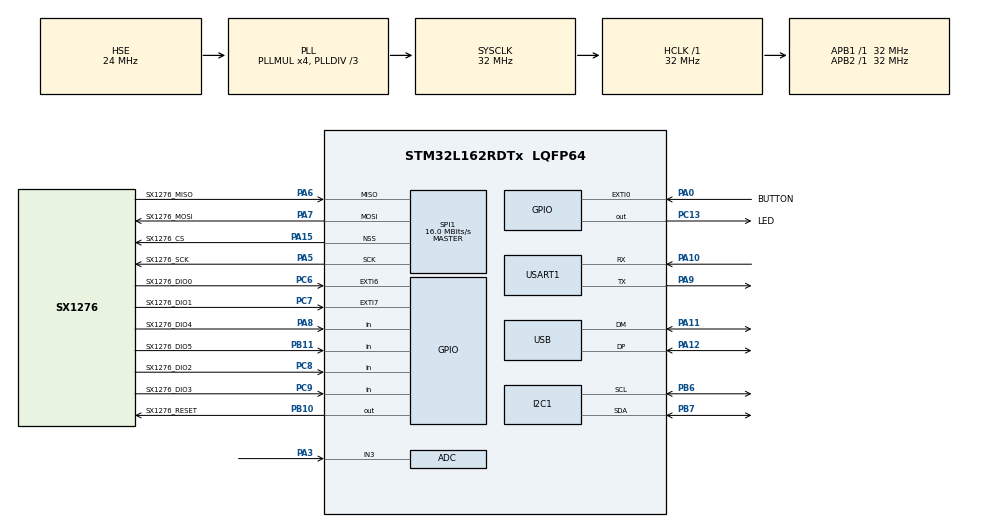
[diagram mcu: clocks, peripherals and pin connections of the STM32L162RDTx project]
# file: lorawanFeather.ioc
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ADC.Channel-1\#ChannelRegularConversion=ADC_CHANNEL_3
ADC.NbrOfConversionFlag=1
ADC.Rank-1\#ChannelRegularConversion=1
ADC.SamplingTime-1\#ChannelRegularConversion=ADC_SAMPLETIME_4CYCLES
Dma.Request0=USART1_TX
Dma.USART1_TX.0.Direction=DMA_MEMORY_TO_PERIPH
Dma.USART1_TX.0.Instance=DMA1_Channel4
Dma.USART1_TX.0.MemDataAlignment=DMA_MDATAALIGN_BYTE
Dma.USART1_TX.0.MemInc=DMA_MINC_ENABLE
Dma.USART1_TX.0.Mode=DMA_NORMAL
Dma.USART1_TX.0.PeriphDataAlignment=DMA_PDATAALIGN_BYTE
Dma.USART1_TX.0.PeriphInc=DMA_PINC_DISABLE
Dma.USART1_TX.0.Priority=DMA_PRIORITY_LOW
Mcu.Family=STM32L1
Mcu.Name=STM32L162RDTx
Mcu.Package=LQFP64
NVIC.DMA1_Channel4_IRQn=true\:0\:0\:false\:false\:true\:false\:true
NVIC.EXTI0_IRQn=true\:0\:0\:false\:false\:true\:true\:true
NVIC.EXTI9_5_IRQn=true\:0\:0\:false\:false\:true\:true\:true
NVIC.I2C1_ER_IRQn=true\:0\:0\:false\:false\:true\:true\:true
NVIC.I2C1_EV_IRQn=true\:0\:0\:false\:false\:true\:true\:true
NVIC.PVD_IRQn=true\:0\:0\:false\:false\:true\:true\:true
NVIC.PriorityGroup=NVIC_PRIORITYGROUP_4
NVIC.RCC_IRQn=true\:0\:0\:false\:false\:true\:true\:false
NVIC.RTC_Alarm_IRQn=true\:0\:0\:false\:false\:true\:true\:true
NVIC.SPI1_IRQn=true\:0\:0\:false\:false\:true\:true\:true
NVIC.USART1_IRQn=true\:0\:0\:false\:false\:true\:true\:true
NVIC.USB_LP_IRQn=true\:0\:0\:false\:false\:true\:false\:true
PA0-WKUP1.GPIO_Label=BUTTON
PA0-WKUP1.Signal=GPXTI0
PA10.Mode=Asynchronous
PA10.Signal=USART1_RX
PA11.Mode=Device
PA11.Signal=USB_DM
PA12.Mode=Device
PA12.Signal=USB_DP
PA13.Mode=Trace_Asynchronous_SW
PA13.Signal=SYS_JTMS-SWDIO
PA14.Mode=Trace_Asynchronous_SW
PA14.Signal=SYS_JTCK-SWCLK
PA15.GPIO_Label=SX1276_CS
PA15.Mode=NSS_Signal_Hard_Output
PA15.Signal=SPI1_NSS
PA3.Mode=IN3
PA3.Signal=ADC_IN3
PA5.GPIO_Label=SX1276_SCK
PA5.Mode=Full_Duplex_Master
PA5.Signal=SPI1_SCK
PA6.GPIO_Label=SX1276_MISO
PA6.Mode=Full_Duplex_Master
PA6.Signal=SPI1_MISO
PA7.GPIO_Label=SX1276_MOSI
PA7.Mode=Full_Duplex_Master
PA7.Signal=SPI1_MOSI
PA8.GPIO_Label=SX1276_DIO4
PA8.Signal=GPIO_Input
PA9.Mode=Asynchronous
PA9.Signal=USART1_TX
PB10.GPIO_Label=SX1276_RESET
PB10.Signal=GPIO_Output
PB11.GPIO_Label=SX1276_DIO5
PB11.Signal=GPIO_Input
PB3.Mode=Trace_Asynchronous_SW
PB3.Signal=SYS_JTDO-TRACESWO
PB6.Mode=I2C
PB6.Signal=I2C1_SCL
PB7.Mode=I2C
PB7.Signal=I2C1_SDA
PC13-WKUP2.GPIO_Label=LED
PC13-WKUP2.Signal=GPIO_Output
PC14-OSC32_IN.Mode=LSE-External-Oscillator
PC14-OSC32_IN.Signal=RCC_OSC32_IN
PC15-OSC32_OUT.Mode=LSE-External-Oscillator
PC15-OSC32_OUT.Signal=RCC_OSC32_OUT
PC6.GPIO_Label=SX1276_DIO0
PC6.Signal=GPXTI6
PC7.GPIO_Label=SX1276_DIO1
PC7.Signal=GPXTI7
PC8.GPIO_Label=SX1276_DIO2
PC8.Signal=GPIO_Input
PC9.GPIO_Label=SX1276_DIO3
PC9.Signal=GPIO_Input
PH0-OSC_IN.Mode=HSE-External-Oscillator
PH0-OSC_IN.Signal=RCC_OSC_IN
PH1-OSC_OUT.Mode=HSE-External-Oscillator
PH1-OSC_OUT.Signal=RCC_OSC_OUT
ProjectManager.HeapSize=0x200
ProjectManager.StackSize=0x400
ProjectManager.TargetToolchain=Makefile
RCC.48MHZClocksFreq_Value=48000000
RCC.AHBFreq_Value=32000000
RCC.APB1Freq_Value=32000000
RCC.APB1TimFreq_Value=32000000
RCC.APB2Freq_Value=32000000
RCC.APB2TimFreq_Value=32000000
RCC.HCLKFreq_Value=32000000
RCC.HSE_VALUE=24000000
RCC.HSI_VALUE=16000000
RCC.MSI_VALUE=2097000
RCC.PLLDIV=RCC_PLL_DIV3
RCC.PLLMUL=RCC_PLL_MUL4
RCC.SYSCLKFreq_VALUE=32000000
RCC.SYSCLKSource=RCC_SYSCLKSOURCE_PLLCLK
RCC.VCOOutputFreq_Value=96000000
RTC.Alarm-Alarm\ A=RTC_ALARM_A
SPI1.CalculateBaudRate=16.0 MBits/s
SPI1.Direction=SPI_DIRECTION_2LINES
SPI1.Mode=SPI_MODE_MASTER
SPI1.VirtualNSS=VM_NSSHARD
SPI1.VirtualType=VM_MASTER
USART1.VirtualMode=VM_ASYNC
USB_DEVICE.CLASS_NAME_FS=CDC
USB_DEVICE.VirtualMode=Cdc
USB_DEVICE.VirtualModeFS=Cdc_FS
VP_ADC_Channel3SpeedFast.Mode=Channel3SpeedFast
VP_RTC_VS_RTC_Activate.Mode=RTC_Enabled
VP_RTC_VS_RTC_Alarm_A_Intern.Mode=Alarm A
VP_RTC_VS_RTC_Calendar.Mode=RTC_Calendar
VP_SYS_V_PVD_IN.Mode=Mode_PVD_Int
VP_USB_DEVICE_VS_USB_DEVICE_CDC_FS.Mode=CDC_FS
board=custom

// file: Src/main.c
/* USER CODE BEGIN Header */
/**
  ******************************************************************************
  * @file           : main.c
  * @brief          : Main program body
  ******************************************************************************
  * @attention
  *
  * <h2><center>&copy; Copyright (c) 2019 STMicroelectronics.
  * All rights reserved.</center></h2>
  *
  * This software component is licensed by ST under Ultimate Liberty license
  * SLA0044, the "License"; You may not use this file except in compliance with
  * the License. You may obtain a copy of the License at:
  *                             www.st.com/SLA0044
  *
  ******************************************************************************
  */
/* USER CODE END Header */

#include "main.h"
#include "usb_device.h"

/* USER CODE BEGIN Includes */
#include "lora.h"
#include "uart_printf.h"

/* USER CODE END Includes */

ADC_HandleTypeDef hadc;

I2C_HandleTypeDef hi2c1;

RTC_HandleTypeDef hrtc;

SPI_HandleTypeDef hspi1;

UART_HandleTypeDef huart1;
DMA_HandleTypeDef hdma_usart1_tx;

void SystemClock_Config(void);
static void MX_GPIO_Init(void);
static void MX_DMA_Init(void);
static void MX_SPI1_Init(void);
static void MX_I2C1_Init(void);
static void MX_USART1_UART_Init(void);
static void MX_RTC_Init(void);
static void MX_ADC_Init(void);

int main(void)
{

  /* MCU Configuration--------------------------------------------------------*/

  /* Reset of all peripherals, Initializes the Flash interface and the Systick. */
  HAL_Init();

  /* Configure the system clock */
  SystemClock_Config();

  /* Initialize all configured peripherals */
  MX_GPIO_Init();
  MX_DMA_Init();
  MX_SPI1_Init();
  MX_I2C1_Init();
  MX_USB_DEVICE_Init();
  MX_USART1_UART_Init();
  MX_RTC_Init();
  MX_ADC_Init();

  /* Infinite loop */
  while (1)
  {
    asm("nop");
  }
}

void SystemClock_Config(void)
{
  RCC_OscInitTypeDef RCC_OscInitStruct = {0};
  RCC_ClkInitTypeDef RCC_ClkInitStruct = {0};
  RCC_PeriphCLKInitTypeDef PeriphClkInit = {0};

  /** Configure the main internal regulator output voltage
  */
  __HAL_PWR_VOLTAGESCALING_CONFIG(PWR_REGULATOR_VOLTAGE_SCALE1);
  /** Initializes the CPU, AHB and APB busses clocks
  */
  RCC_OscInitStruct.OscillatorType = RCC_OSCILLATORTYPE_HSI|RCC_OSCILLATORTYPE_LSI
                              |RCC_OSCILLATORTYPE_HSE;
  RCC_OscInitStruct.HSEState = RCC_HSE_ON;
  RCC_OscInitStruct.HSIState = RCC_HSI_ON;
  RCC_OscInitStruct.HSICalibrationValue = RCC_HSICALIBRATION_DEFAULT;
  RCC_OscInitStruct.LSIState = RCC_LSI_ON;
  RCC_OscInitStruct.PLL.PLLState = RCC_PLL_ON;
  RCC_OscInitStruct.PLL.PLLSource = RCC_PLLSOURCE_HSE;
  RCC_OscInitStruct.PLL.PLLMUL = RCC_PLL_MUL4;
  RCC_OscInitStruct.PLL.PLLDIV = RCC_PLL_DIV3;
  if (HAL_RCC_OscConfig(&RCC_OscInitStruct) != HAL_OK)
  {
    Error_Handler();
  }
  /** Initializes the CPU, AHB and APB busses clocks
  */
  RCC_ClkInitStruct.ClockType = RCC_CLOCKTYPE_HCLK|RCC_CLOCKTYPE_SYSCLK
                              |RCC_CLOCKTYPE_PCLK1|RCC_CLOCKTYPE_PCLK2;
  RCC_ClkInitStruct.SYSCLKSource = RCC_SYSCLKSOURCE_PLLCLK;
  RCC_ClkInitStruct.AHBCLKDivider = RCC_SYSCLK_DIV1;
  RCC_ClkInitStruct.APB1CLKDivider = RCC_HCLK_DIV1;
  RCC_ClkInitStruct.APB2CLKDivider = RCC_HCLK_DIV1;

  if (HAL_RCC_ClockConfig(&RCC_ClkInitStruct, FLASH_LATENCY_1) != HAL_OK)
  {
    Error_Handler();
  }
  PeriphClkInit.PeriphClockSelection = RCC_PERIPHCLK_RTC;
  PeriphClkInit.RTCClockSelection = RCC_RTCCLKSOURCE_LSI;
  if (HAL_RCCEx_PeriphCLKConfig(&PeriphClkInit) != HAL_OK)
  {
    Error_Handler();
  }
}

static void MX_ADC_Init(void)
{

  ADC_ChannelConfTypeDef sConfig = {0};

  /** Configure the global features of the ADC (Clock, Resolution, Data Alignment and number of conversion)
  */
  hadc.Instance = ADC1;
  hadc.Init.ClockPrescaler = ADC_CLOCK_ASYNC_DIV1;
  hadc.Init.Resolution = ADC_RESOLUTION_12B;
  hadc.Init.DataAlign = ADC_DATAALIGN_RIGHT;
  hadc.Init.ScanConvMode = ADC_SCAN_DISABLE;
  hadc.Init.EOCSelection = ADC_EOC_SEQ_CONV;
  hadc.Init.LowPowerAutoWait = ADC_AUTOWAIT_DISABLE;
  hadc.Init.LowPowerAutoPowerOff = ADC_AUTOPOWEROFF_DISABLE;
  hadc.Init.ChannelsBank = ADC_CHANNELS_BANK_A;
  hadc.Init.ContinuousConvMode = DISABLE;
  hadc.Init.NbrOfConversion = 1;
  hadc.Init.DiscontinuousConvMode = DISABLE;
  hadc.Init.ExternalTrigConv = ADC_SOFTWARE_START;
  hadc.Init.ExternalTrigConvEdge = ADC_EXTERNALTRIGCONVEDGE_NONE;
  hadc.Init.DMAContinuousRequests = DISABLE;
  if (HAL_ADC_Init(&hadc) != HAL_OK)
  {
    Error_Handler();
  }
  /** Configure the channel speed in Fast mode
  */
  __HAL_ADC_CHANNEL_SPEED_FAST(ADC_CHANNEL_3);
  /** Configure for the selected ADC regular channel its corresponding rank in the sequencer and its sample time.
  */
  sConfig.Channel = ADC_CHANNEL_3;
  sConfig.Rank = ADC_REGULAR_RANK_1;
  sConfig.SamplingTime = ADC_SAMPLETIME_4CYCLES;
  if (HAL_ADC_ConfigChannel(&hadc, &sConfig) != HAL_OK)
  {
    Error_Handler();
  }

}

static void MX_I2C1_Init(void)
{

  hi2c1.Instance = I2C1;
  hi2c1.Init.ClockSpeed = 100000;
  hi2c1.Init.DutyCycle = I2C_DUTYCYCLE_2;
  hi2c1.Init.OwnAddress1 = 0;
  hi2c1.Init.AddressingMode = I2C_ADDRESSINGMODE_7BIT;
  hi2c1.Init.DualAddressMode = I2C_DUALADDRESS_DISABLE;
  hi2c1.Init.OwnAddress2 = 0;
  hi2c1.Init.GeneralCallMode = I2C_GENERALCALL_DISABLE;
  hi2c1.Init.NoStretchMode = I2C_NOSTRETCH_DISABLE;
  if (HAL_I2C_Init(&hi2c1) != HAL_OK)
  {
    Error_Handler();
  }

}

static void MX_RTC_Init(void)
{

  RTC_TimeTypeDef sTime = {0};
  RTC_DateTypeDef sDate = {0};
  RTC_AlarmTypeDef sAlarm = {0};

  /** Initialize RTC Only
  */
  hrtc.Instance = RTC;
  hrtc.Init.HourFormat = RTC_HOURFORMAT_24;
  hrtc.Init.AsynchPrediv = 127;
  hrtc.Init.SynchPrediv = 255;
  hrtc.Init.OutPut = RTC_OUTPUT_DISABLE;
  hrtc.Init.OutPutPolarity = RTC_OUTPUT_POLARITY_HIGH;
  hrtc.Init.OutPutType = RTC_OUTPUT_TYPE_OPENDRAIN;
  if (HAL_RTC_Init(&hrtc) != HAL_OK)
  {
    Error_Handler();
  }

  /** Initialize RTC and set the Time and Date
  */
  sTime.Hours = 0x0;
  sTime.Minutes = 0x0;
  sTime.Seconds = 0x0;
  sTime.DayLightSaving = RTC_DAYLIGHTSAVING_NONE;
  sTime.StoreOperation = RTC_STOREOPERATION_RESET;
  if (HAL_RTC_SetTime(&hrtc, &sTime, RTC_FORMAT_BCD) != HAL_OK)
  {
    Error_Handler();
  }
  sDate.WeekDay = RTC_WEEKDAY_MONDAY;
  sDate.Month = RTC_MONTH_JANUARY;
  sDate.Date = 0x1;
  sDate.Year = 0x0;

  if (HAL_RTC_SetDate(&hrtc, &sDate, RTC_FORMAT_BCD) != HAL_OK)
  {
    Error_Handler();
  }
  /** Enable the Alarm A
  */
  sAlarm.AlarmTime.Hours = 0x0;
  sAlarm.AlarmTime.Minutes = 0x0;
  sAlarm.AlarmTime.Seconds = 0x0;
  sAlarm.AlarmTime.SubSeconds = 0x0;
  sAlarm.AlarmTime.DayLightSaving = RTC_DAYLIGHTSAVING_NONE;
  sAlarm.AlarmTime.StoreOperation = RTC_STOREOPERATION_RESET;
  sAlarm.AlarmMask = RTC_ALARMMASK_NONE;
  sAlarm.AlarmSubSecondMask = RTC_ALARMSUBSECONDMASK_ALL;
  sAlarm.AlarmDateWeekDaySel = RTC_ALARMDATEWEEKDAYSEL_DATE;
  sAlarm.AlarmDateWeekDay = 0x1;
  sAlarm.Alarm = RTC_ALARM_A;
  if (HAL_RTC_SetAlarm_IT(&hrtc, &sAlarm, RTC_FORMAT_BCD) != HAL_OK)
  {
    Error_Handler();
  }

}

static void MX_SPI1_Init(void)
{

  /* SPI1 parameter configuration*/
  hspi1.Instance = SPI1;
  hspi1.Init.Mode = SPI_MODE_MASTER;
  hspi1.Init.Direction = SPI_DIRECTION_2LINES;
  hspi1.Init.DataSize = SPI_DATASIZE_8BIT;
  hspi1.Init.CLKPolarity = SPI_POLARITY_LOW;
  hspi1.Init.CLKPhase = SPI_PHASE_1EDGE;
  hspi1.Init.NSS = SPI_NSS_HARD_OUTPUT;
  hspi1.Init.BaudRatePrescaler = SPI_BAUDRATEPRESCALER_2;
  hspi1.Init.FirstBit = SPI_FIRSTBIT_MSB;
  hspi1.Init.TIMode = SPI_TIMODE_DISABLE;
  hspi1.Init.CRCCalculation = SPI_CRCCALCULATION_DISABLE;
  hspi1.Init.CRCPolynomial = 10;
  if (HAL_SPI_Init(&hspi1) != HAL_OK)
  {
    Error_Handler();
  }

}

static void MX_USART1_UART_Init(void)
{

  huart1.Instance = USART1;
  huart1.Init.BaudRate = 115200;
  huart1.Init.WordLength = UART_WORDLENGTH_8B;
  huart1.Init.StopBits = UART_STOPBITS_1;
  huart1.Init.Parity = UART_PARITY_NONE;
  huart1.Init.Mode = UART_MODE_TX_RX;
  huart1.Init.HwFlowCtl = UART_HWCONTROL_NONE;
  huart1.Init.OverSampling = UART_OVERSAMPLING_16;
  if (HAL_UART_Init(&huart1) != HAL_OK)
  {
    Error_Handler();
  }

}

static void MX_DMA_Init(void)
{
  /* DMA controller clock enable */
  __HAL_RCC_DMA1_CLK_ENABLE();

  /* DMA interrupt init */
  /* DMA1_Channel4_IRQn interrupt configuration */
  HAL_NVIC_SetPriority(DMA1_Channel4_IRQn, 0, 0);
  HAL_NVIC_EnableIRQ(DMA1_Channel4_IRQn);

}

static void MX_GPIO_Init(void)
{
  GPIO_InitTypeDef GPIO_InitStruct = {0};

  /* GPIO Ports Clock Enable */
  __HAL_RCC_GPIOC_CLK_ENABLE();
  __HAL_RCC_GPIOH_CLK_ENABLE();
  __HAL_RCC_GPIOA_CLK_ENABLE();
  __HAL_RCC_GPIOB_CLK_ENABLE();

  /*Configure GPIO pin Output Level */
  HAL_GPIO_WritePin(LED_GPIO_Port, LED_Pin, GPIO_PIN_RESET);

  /*Configure GPIO pin Output Level */
  HAL_GPIO_WritePin(SX1276_RESET_GPIO_Port, SX1276_RESET_Pin, GPIO_PIN_RESET);

  /*Configure GPIO pin : LED_Pin */
  GPIO_InitStruct.Pin = LED_Pin;
  GPIO_InitStruct.Mode = GPIO_MODE_OUTPUT_PP;
  GPIO_InitStruct.Pull = GPIO_NOPULL;
  GPIO_InitStruct.Speed = GPIO_SPEED_FREQ_LOW;
  HAL_GPIO_Init(LED_GPIO_Port, &GPIO_InitStruct);

  /*Configure GPIO pin : BUTTON_Pin */
  GPIO_InitStruct.Pin = BUTTON_Pin;
  GPIO_InitStruct.Mode = GPIO_MODE_IT_RISING;
  GPIO_InitStruct.Pull = GPIO_NOPULL;
  HAL_GPIO_Init(BUTTON_GPIO_Port, &GPIO_InitStruct);

  /*Configure GPIO pin : SX1276_RESET_Pin */
  GPIO_InitStruct.Pin = SX1276_RESET_Pin;
  GPIO_InitStruct.Mode = GPIO_MODE_OUTPUT_PP;
  GPIO_InitStruct.Pull = GPIO_NOPULL;
  GPIO_InitStruct.Speed = GPIO_SPEED_FREQ_LOW;
  HAL_GPIO_Init(SX1276_RESET_GPIO_Port, &GPIO_InitStruct);

  /*Configure GPIO pin : SX1276_DIO5_Pin */
  GPIO_InitStruct.Pin = SX1276_DIO5_Pin;
  GPIO_InitStruct.Mode = GPIO_MODE_INPUT;
  GPIO_InitStruct.Pull = GPIO_NOPULL;
  HAL_GPIO_Init(SX1276_DIO5_GPIO_Port, &GPIO_InitStruct);

  /*Configure GPIO pins : SX1276_DIO0_Pin SX1276_DIO1_Pin */
  GPIO_InitStruct.Pin = SX1276_DIO0_Pin|SX1276_DIO1_Pin;
  GPIO_InitStruct.Mode = GPIO_MODE_IT_RISING;
  GPIO_InitStruct.Pull = GPIO_NOPULL;
  HAL_GPIO_Init(GPIOC, &GPIO_InitStruct);

  /*Configure GPIO pins : SX1276_DIO2_Pin SX1276_DIO3_Pin */
  GPIO_InitStruct.Pin = SX1276_DIO2_Pin|SX1276_DIO3_Pin;
  GPIO_InitStruct.Mode = GPIO_MODE_INPUT;
  GPIO_InitStruct.Pull = GPIO_NOPULL;
  HAL_GPIO_Init(GPIOC, &GPIO_InitStruct);

  /*Configure GPIO pin : SX1276_DIO4_Pin */
  GPIO_InitStruct.Pin = SX1276_DIO4_Pin;
  GPIO_InitStruct.Mode = GPIO_MODE_INPUT;
  GPIO_InitStruct.Pull = GPIO_NOPULL;
  HAL_GPIO_Init(SX1276_DIO4_GPIO_Port, &GPIO_InitStruct);

  /* EXTI interrupt init*/
  HAL_NVIC_SetPriority(EXTI0_IRQn, 0, 0);
  HAL_NVIC_EnableIRQ(EXTI0_IRQn);

  HAL_NVIC_SetPriority(EXTI9_5_IRQn, 0, 0);
  HAL_NVIC_EnableIRQ(EXTI9_5_IRQn);

}

void Error_Handler(void)
{
}

/************************ (C) COPYRIGHT STMicroelectronics *****END OF FILE****/
